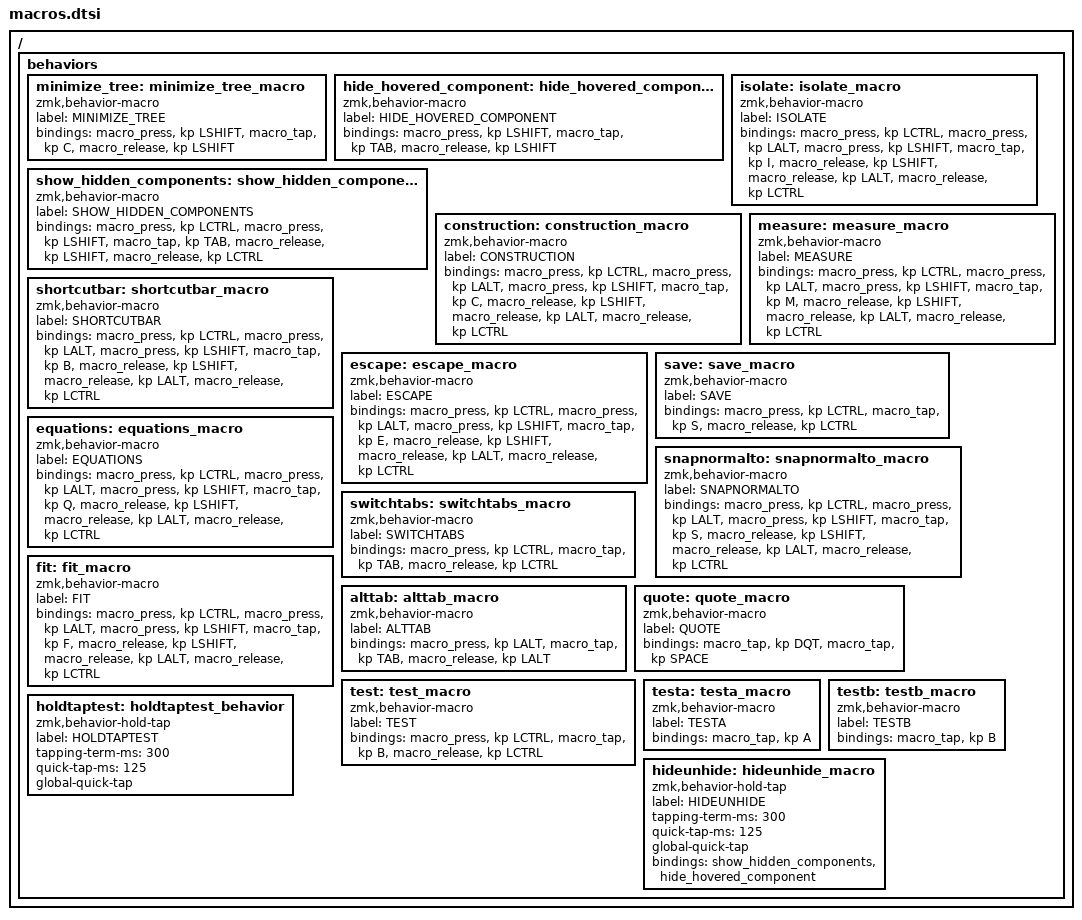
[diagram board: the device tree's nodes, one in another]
/* config/macros.dtsi */
#include <behaviors.dtsi>
#include <dt-bindings/zmk/keys.h>

/ {
    behaviors {
        minimize_tree: minimize_tree_macro {
            compatible = "zmk,behavior-macro";
            label = "MINIMIZE_TREE";
            #binding-cells = <0>;
            bindings 
                = <&macro_press &kp LSHIFT>
                , <&macro_tap &kp C>
                , <&macro_release &kp LSHIFT>;
        };

        hide_hovered_component: hide_hovered_component_macro {
            compatible = "zmk,behavior-macro";
            label = "HIDE_HOVERED_COMPONENT";
            #binding-cells = <0>;
            bindings 
                = <&macro_press &kp LSHIFT>
                , <&macro_tap &kp TAB>
                , <&macro_release &kp LSHIFT>;
        };

         show_hidden_components: show_hidden_components_macro {
            compatible = "zmk,behavior-macro";
            label = "SHOW_HIDDEN_COMPONENTS";
            #binding-cells = <0>;
            bindings 
                = <&macro_press &kp LCTRL>
                , <&macro_press &kp LSHIFT>
                , <&macro_tap &kp TAB>
                , <&macro_release &kp LSHIFT>
                , <&macro_release &kp LCTRL>;
        };

        isolate: isolate_macro {
            compatible = "zmk,behavior-macro";
            label = "ISOLATE";
            #binding-cells = <0>;
            bindings 
                = <&macro_press &kp LCTRL>
                , <&macro_press &kp LALT>
                , <&macro_press &kp LSHIFT>
                , <&macro_tap &kp I>
                , <&macro_release &kp LSHIFT>
                , <&macro_release &kp LALT>
                , <&macro_release &kp LCTRL>;
        };

        construction: construction_macro {
            compatible = "zmk,behavior-macro";
            label = "CONSTRUCTION";
            #binding-cells = <0>;
            bindings 
                = <&macro_press &kp LCTRL>
                , <&macro_press &kp LALT>
                , <&macro_press &kp LSHIFT>
                , <&macro_tap &kp C>
                , <&macro_release &kp LSHIFT>
                , <&macro_release &kp LALT>
                , <&macro_release &kp LCTRL>;
        };

        measure: measure_macro {
            compatible = "zmk,behavior-macro";
            label = "MEASURE";
            #binding-cells = <0>;
            bindings 
                = <&macro_press &kp LCTRL>
                , <&macro_press &kp LALT>
                , <&macro_press &kp LSHIFT>
                , <&macro_tap &kp M>
                , <&macro_release &kp LSHIFT>
                , <&macro_release &kp LALT>
                , <&macro_release &kp LCTRL>;
        };

        shortcutbar: shortcutbar_macro {
            compatible = "zmk,behavior-macro";
            label = "SHORTCUTBAR";
            #binding-cells = <0>;
            bindings 
                = <&macro_press &kp LCTRL>
                , <&macro_press &kp LALT>
                , <&macro_press &kp LSHIFT>
                , <&macro_tap &kp B>
                , <&macro_release &kp LSHIFT>
                , <&macro_release &kp LALT>
                , <&macro_release &kp LCTRL>;
        };

        escape: escape_macro {
            compatible = "zmk,behavior-macro";
            label = "ESCAPE";
            #binding-cells = <0>;
            bindings 
                = <&macro_press &kp LCTRL>
                , <&macro_press &kp LALT>
                , <&macro_press &kp LSHIFT>
                , <&macro_tap &kp E>
                , <&macro_release &kp LSHIFT>
                , <&macro_release &kp LALT>
                , <&macro_release &kp LCTRL>;
        };

        save: save_macro {
            compatible = "zmk,behavior-macro";
            label = "SAVE";
            #binding-cells = <0>;
            bindings 
                = <&macro_press &kp LCTRL>
                , <&macro_tap &kp S>
                , <&macro_release &kp LCTRL>;
        };

        equations: equations_macro {
            compatible = "zmk,behavior-macro";
            label = "EQUATIONS";
            #binding-cells = <0>;
            bindings 
                = <&macro_press &kp LCTRL>
                , <&macro_press &kp LALT>
                , <&macro_press &kp LSHIFT>
                , <&macro_tap &kp Q>
                , <&macro_release &kp LSHIFT>
                , <&macro_release &kp LALT>
                , <&macro_release &kp LCTRL>;
        };

        snapnormalto: snapnormalto_macro {
            compatible = "zmk,behavior-macro";
            label = "SNAPNORMALTO";
            #binding-cells = <0>;
            bindings 
                = <&macro_press &kp LCTRL>
                , <&macro_press &kp LALT>
                , <&macro_press &kp LSHIFT>
                , <&macro_tap &kp S>
                , <&macro_release &kp LSHIFT>
                , <&macro_release &kp LALT>
                , <&macro_release &kp LCTRL>;
        };

        switchtabs: switchtabs_macro {
            compatible = "zmk,behavior-macro";
            label = "SWITCHTABS";
            #binding-cells = <0>;
            bindings 
                = <&macro_press &kp LCTRL>
                , <&macro_tap &kp TAB>
                , <&macro_release &kp LCTRL>;
        };

        fit: fit_macro {
            compatible = "zmk,behavior-macro";
            label = "FIT";
            #binding-cells = <0>;
            bindings 
                = <&macro_press &kp LCTRL>
                , <&macro_press &kp LALT>
                , <&macro_press &kp LSHIFT>
                , <&macro_tap &kp F>
                , <&macro_release &kp LSHIFT>
                , <&macro_release &kp LALT>
                , <&macro_release &kp LCTRL>;
        };

        alttab: alttab_macro {
            compatible = "zmk,behavior-macro";
            label = "ALTTAB";
            #binding-cells = <0>;
            bindings 
                = <&macro_press &kp LALT>
                , <&macro_tap &kp TAB>
                , <&macro_release &kp LALT>;
        };

        quote: quote_macro {
            compatible = "zmk,behavior-macro";
            label = "QUOTE";
            #binding-cells = <0>;
            bindings 
                = <&macro_tap &kp DQT>
                , <&macro_tap &kp SPACE>;
        };

        test: test_macro {
            compatible = "zmk,behavior-macro";
            label = "TEST";
            #binding-cells = <0>;
            bindings 
                = <&macro_press &kp LCTRL>
                , <&macro_tap &kp B>
                , <&macro_release &kp LCTRL>;
        };

        testa: testa_macro {
            compatible = "zmk,behavior-macro";
            label = "TESTA";
            #binding-cells = <0>;
            bindings 
                = <&macro_tap &kp A>;
        };

        testb: testb_macro {
            compatible = "zmk,behavior-macro";
            label = "TESTB";
            #binding-cells = <0>;
            bindings 
                = <&macro_tap &kp B>;
        };

        holdtaptest: holdtaptest_behavior {
            compatible = "zmk,behavior-hold-tap";
            label = "HOLDTAPTEST";
            #binding-cells = <2>;
            tapping-term-ms = <300>;
            quick-tap-ms = <125>;
            global-quick-tap;
        };


       hideunhide: hideunhide_macro {
            compatible = "zmk,behavior-hold-tap";
            label = "HIDEUNHIDE";
            #binding-cells = <2>;
            tapping-term-ms = <300>;
            quick-tap-ms = <125>;
            global-quick-tap;
            bindings
                = <&show_hidden_components>
                , <&hide_hovered_component>;
        };
    };
};
